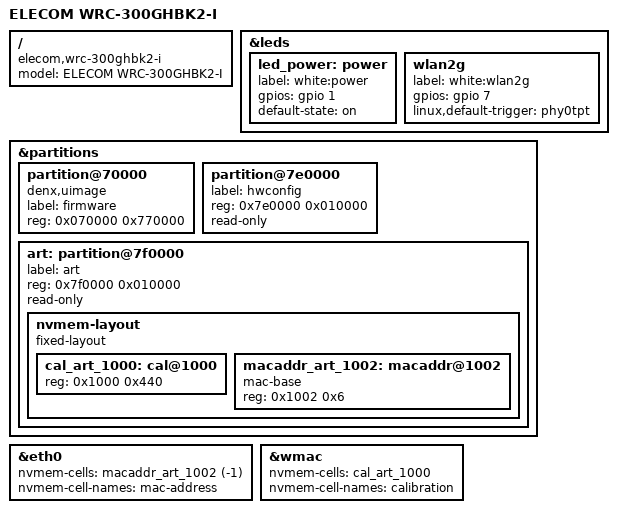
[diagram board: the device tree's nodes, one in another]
// SPDX-License-Identifier: GPL-2.0-or-later OR MIT

#include "qca9563_elecom_wrc-ghbk2-i.dtsi"

/ {
	model = "ELECOM WRC-300GHBK2-I";
	compatible = "elecom,wrc-300ghbk2-i", "qca,qca9563";
};

&leds {
	led_power: power {
		label = "white:power";
		gpios = <&gpio 1 GPIO_ACTIVE_HIGH>;
		default-state = "on";
	};

	wlan2g {
		label = "white:wlan2g";
		gpios = <&gpio 7 GPIO_ACTIVE_HIGH>;
		linux,default-trigger = "phy0tpt";
	};
};

&partitions {
	partition@70000 {
		compatible = "denx,uimage";
		label = "firmware";
		reg = <0x070000 0x770000>;
	};

	partition@7e0000 {
		label = "hwconfig";
		reg = <0x7e0000 0x010000>;
		read-only;
	};

	art: partition@7f0000 {
		label = "art";
		reg = <0x7f0000 0x010000>;
		read-only;

		nvmem-layout {
			compatible = "fixed-layout";
			#address-cells = <1>;
			#size-cells = <1>;

			cal_art_1000: cal@1000 {
				reg = <0x1000 0x440>;
			};

			macaddr_art_1002: macaddr@1002 {
				compatible = "mac-base";
				reg = <0x1002 0x6>;
				#nvmem-cell-cells = <1>;
			};
		};
	};
};

&eth0 {
	nvmem-cells = <&macaddr_art_1002 (-1)>;
	nvmem-cell-names = "mac-address";
};

&wmac {
	nvmem-cells = <&cal_art_1000>;
	nvmem-cell-names = "calibration";
};
